# STM32U3C5xx register map
File version: 1.0
Registers are 32-bit, read-write, reset 0x0 unless marked. A register's access mark holds for its fields unless they carry their own. Offsets are from the block's base; [hi:lo] are bit positions; {n}, {i} and the like mark numbered series.

## TIM6 — TIM
Base 0x40001000
Same registers: TIM7 0x40001400
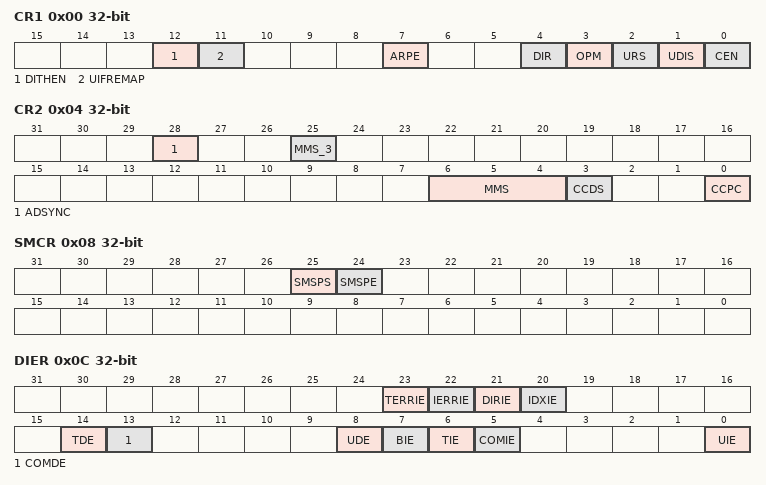
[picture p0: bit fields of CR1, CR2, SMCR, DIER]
0x00 CR1 — TIM control register 1
  [12] DITHEN — Dithering enable
  [11] UIFREMAP — Update interrupt flag remap
  [7] ARPE — Auto-reload preload enable
  [4] DIR — Direction
    0=UP (Timer counter counts up); 1=DOWN (Timer counter counts down)
  [3] OPM — One pulse mode
    1=SINGLE (Counter stops counting at the next update event); 0=REPETITIVE (Counter is not stopped at update event)
  [2] URS — Update request source
    0=REGULAR (Counter overflow/underflow, Setting the UG bit or Update generation through the slave mode controller generates an update request); 1=COUNTER (Only counter overflow/underflow generates an update request)
  [1] UDIS — Update disable
  [0] CEN — Counter enable
0x04 CR2 — TIM control register 2
  [28] ADSYNC — ADC synchronization
  [25] MMS_3 — MMS[3:0] bits (Master Mode Selection)
  [6:4] MMS — MMS[3:0] bits (Master Mode Selection)
  [3] CCDS — Capture/Compare DMA Selection
    0=CC (CCx DMA request sent when CCx event occurs); 1=UPDATE (CCx DMA requests sent when update event occurs)
  [0] CCPC — Capture/Compare Preloaded Control
0x08 SMCR — TIM slave mode control register
  [25] SMSPS — SMS preload source
    0=TIMUPDATE (The SMS preload transfer is triggered by the Timer's Update event); 1=INDEX (The SMS preload transfer is triggered by the Index event)
  [24] SMSPE — SMS preload enable
0x0C DIER — TIM DMA/interrupt enable register
  [23] TERRIE — Encoder transition error enable
  [22] IERRIE — Encoder index error enable
  [21] DIRIE — Encoder direction change interrupt enable
  [20] IDXIE — Encoder index interrupt enable
  [14] TDE — Trigger DMA request enable
  [13] COMDE — COM DMA request enable
  [8] UDE — Update DMA request enable
  [7] BIE — Break interrupt enable
  [6] TIE — Trigger interrupt enable
  [5] COMIE — COM interrupt enable
  [0] UIE — Update interrupt enable
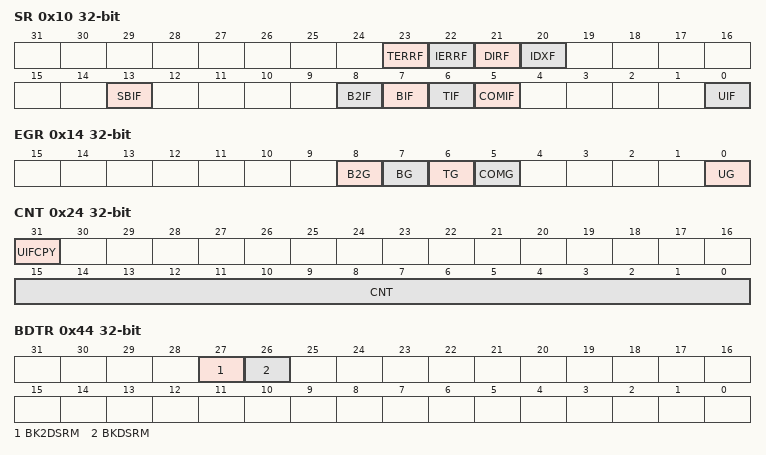
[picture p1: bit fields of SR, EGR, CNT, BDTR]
0x10 SR — TIM status register
  [23] TERRF — Encoder transition error flag
  [22] IERRF — Encoder index error flag
  [21] DIRF — Encoder direction change interrupt flag
  [20] IDXF — Encoder index interrupt flag
  [13] SBIF — System Break interrupt Flag
  [8] B2IF — Break 2 interrupt Flag
  [7] BIF — Break interrupt Flag
  [6] TIF — Trigger interrupt Flag
  [5] COMIF — COM interrupt Flag
  [0] UIF — Update interrupt Flag
0x14 EGR — TIM event generation register
  [8] B2G — Break 2 Generation
  [7] BG — Break Generation
  [6] TG — Trigger Generation
  [5] COMG — Capture/Compare Control Update Generation
  [0] UG — Update Generation
0x24 CNT — TIM counter register
  [31] UIFCPY — Update interrupt flag copy (if UIFREMAP=1)
  [15:0] CNT — Counter Value
0x28 PSC — TIM prescaler
  [15:0] PSC — Prescaler Value
0x2C ARR — TIM auto-reload register
  [15:0] ARR — Actual auto-reload Value
0x44 BDTR — TIM break and dead-time register
  [27] BK2DSRM — Break2 disarming/re-arming
  [26] BKDSRM — Break disarming/re-arming
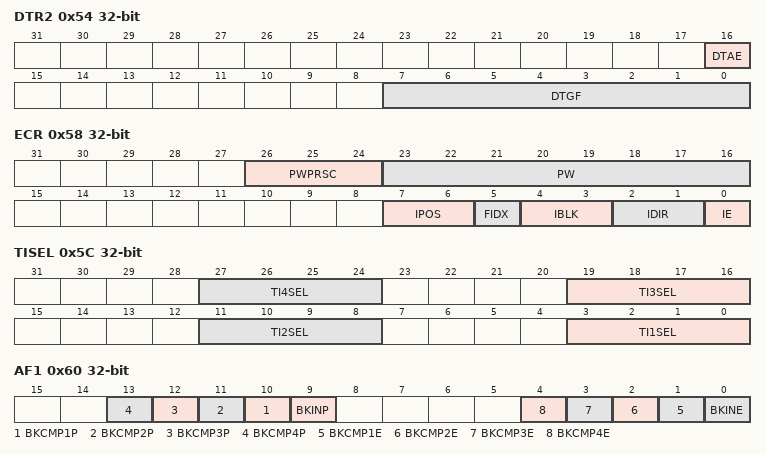
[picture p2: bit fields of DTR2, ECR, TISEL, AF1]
0x54 DTR2 — TIM deadtime register 2
  [16] DTAE — Deadtime asymmetric enable
  [7:0] DTGF — DTGF[7:0] bits (Deadtime falling edge generator setup)
0x58 ECR — TIM encoder control register
  [26:24] PWPRSC — PWPRSC[2:0] bits (Pulse width prescaler)
    0=Pulse on compare pulse width prescaler 1; 1=X2 (Pulse on compare pulse width prescaler 2); 2=X4 (Pulse on compare pulse width prescaler 4); 3=X8 (Pulse on compare pulse width prescaler 8); 4=X16 (Pulse on compare pulse width prescaler 16); 5=X32 (Pulse on compare pulse width prescaler 32); 6=X64 (Pulse on compare pulse width prescaler 64); 7=X128 (Pulse on compare pulse width prescaler 128)
  [23:16] PW — PW[7:0] bits (Pulse width)
  [7:6] IPOS — IPOS[1:0] bits (Index positioning)
    0=DOWN_DOWN (Index resets the counter when AB = 00); 1=DOWN_UP (Index resets the counter when AB = 01); 2=UP_DOWN (Index resets the counter when AB = 10); 3=UP_UP (Index resets the counter when AB = 11)
  [5] FIDX — First index enable
  [4:3] IBLK — IBLK[1:0] bits (Index blanking)
    0=ALWAYS (Index always active); 1=TI3 (Index disabled when TI3 input is active, as per CC3P bitfield); 2=TI4 (Index disabled when TI4 input is active, as per CC4P bitfield)
  [2:1] IDIR — IDIR[1:0] bits (Index direction)
    0=UP_DOWN (Index resets the counter whatever the direction); 1=UP (Index resets the counter when up-counting only); 2=DOWN (Index resets the counter when down-counting only)
  [0] IE — Index enable
0x5C TISEL — TIM Input Selection register
  [8n-5:8n-8] TI{n}SEL (n=1..4) — TI{n}SEL[3:0] bits (TIM1 TI{n} SEL)
0x60 AF1 — TIM alternate function option register 1
  [n+9] BKCMP{n}P (n=1..4) — BRK CMP{n} input polarity
  [9] BKINP — BRK BKIN input polarity
  [n] BKCMP{n}E (n=1..4) — BRK CMP{n} enable
  [0] BKINE — BRK BKIN input enable
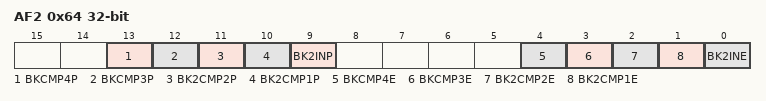
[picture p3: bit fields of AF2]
0x64 AF2 — TIM alternate function option register 2
  [13] BKCMP4P — BRK CMP4 input polarity
  [12] BKCMP3P — BRK CMP3 input polarity
  [11] BK2CMP2P — BRK2 CMP2 input polarity
  [10] BK2CMP1P — BRK2 CMP1 input polarity
  [9] BK2INP — BRK2 BKIN input polarity
  [4] BKCMP4E — BRK CMP4 enable
  [3] BKCMP3E — BRK CMP3 enable
  [2] BK2CMP2E — BRK2 CMP2 enable
  [1] BK2CMP1E — BRK2 CMP1 enable
  [0] BK2INE — BRK2 BKIN input enable
0x68 OR1 — TIM option register
  [1] HSE32EN — HSE/32 clock enable
0x3E0 DMAR — TIM DMA address for full transfer
  [31:0] DMAB — DMA register for burst accesses
